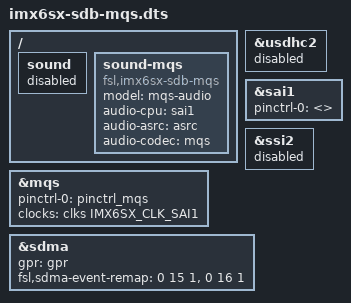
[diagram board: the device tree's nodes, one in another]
// SPDX-License-Identifier: GPL-2.0
//
// Copyright (C) 2014 Freescale Semiconductor, Inc.

#include "imx6sx-sdb.dts"
/ {

	sound {
		status = "disabled";
	};

	sound-mqs {
		compatible = "fsl,imx6sx-sdb-mqs",
			     "fsl,imx-audio-mqs";
		model = "mqs-audio";
		audio-cpu = <&sai1>;
		audio-asrc = <&asrc>;
		audio-codec = <&mqs>;
	};
};

&usdhc2 {
	/* pin conflict with mqs*/
	status = "disabled";
};

&mqs {
	pinctrl-names = "default";
	pinctrl-0 = <&pinctrl_mqs>;
	clocks = <&clks IMX6SX_CLK_SAI1>;
	clock-names = "mclk";
	status = "okay";
};

&sai1 {
	pinctrl-0 = <>;
	status = "okay";
};

&ssi2 {
	status = "disabled";
};

&sdma {
	gpr = <&gpr>;
	/* SDMA event remap for SAI1 */
	fsl,sdma-event-remap = <0 15 1>, <0 16 1>;
};
